AUTOSAR XML (schema 00046)
package /SWComponent
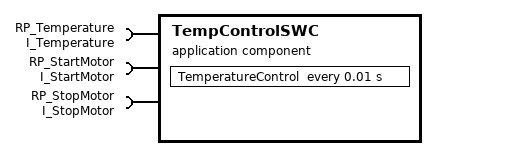
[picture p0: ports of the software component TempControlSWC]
  application sw component type TempControlSWC
    require port RP_Temperature: required-interface=I_Temperature
    require port RP_StartMotor: required-interface=I_StartMotor
    require port RP_StopMotor: required-interface=I_StopMotor
    behavior IB_SWC
      timing event TE_10ms: start-on-event=TemperatureControl, period=0.01
      runnable TemperatureControl: symbol=TemperatureControl_Function
        data-receive-point-by-arguments:
          access VA_Temp: accessed-variable=RP_Temperature.Temperature
        sync call SC_StartMotor: operation=RP_StartMotor.StartMotor
        sync call SC_StopMotor: operation=RP_StopMotor.StopMotor
